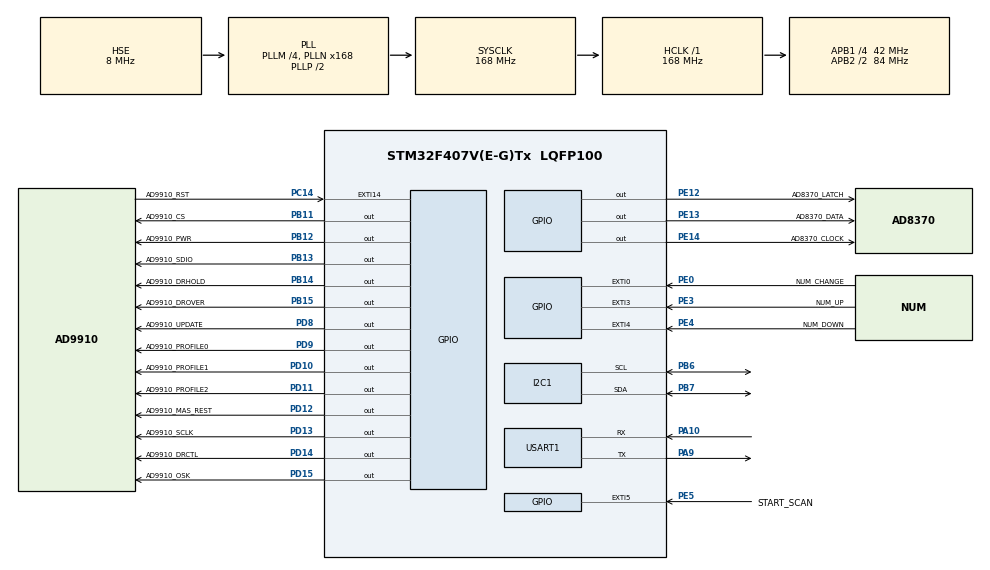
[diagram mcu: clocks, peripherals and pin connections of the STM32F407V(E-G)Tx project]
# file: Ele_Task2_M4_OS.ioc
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Mcu.Family=STM32F4
PD12.GPIO_Label=AD9910_MAS_REST
PH0-OSC_IN.Signal=RCC_OSC_IN
PE14.GPIO_Speed=GPIO_SPEED_FREQ_HIGH
RCC.CortexFreq_Value=168000000
PD15.GPIO_Speed=GPIO_SPEED_FREQ_HIGH
PB14.GPIO_Label=AD9910_DRHOLD
PD9.GPIO_Speed=GPIO_SPEED_FREQ_HIGH
NVIC.EXTI3_IRQn=true\:5\:0\:false\:false\:true\:true\:true\:true
PB13.GPIO_Label=AD9910_SDIO
PB11.Signal=GPIO_Output
PB13.Signal=GPIO_Output
PB15.Signal=GPIO_Output
FREERTOS.configUSE_TASK_NOTIFICATIONS=1
RCC.SYSCLKSource=RCC_SYSCLKSOURCE_PLLCLK
ProjectManager.StackSize=0x400
PB11.GPIO_Speed=GPIO_SPEED_FREQ_HIGH
PD13.Signal=GPIO_Output
PD14.GPIO_Speed=GPIO_SPEED_FREQ_HIGH
FREERTOS.configENABLE_FPU=1
PE5.GPIO_PuPd=GPIO_PULLUP
PD11.GPIO_Label=AD9910_PROFILE2
RCC.HCLKFreq_Value=168000000
RCC.APB2TimFreq_Value=168000000
PB6.Signal=I2C1_SCL
PB6.Mode=I2C
PD8.Signal=GPIO_Output
PE5.Signal=GPXTI5
FREERTOS.configMINIMAL_STACK_SIZE=64
RCC.AHBFreq_Value=168000000
PH0-OSC_IN.Mode=HSE-External-Oscillator
RCC.HSE_VALUE=8000000
PB12.GPIO_Label=AD9910_PWR
PE13.Signal=GPIO_Output
PA14.Mode=Serial_Wire
VP_SYS_VS_tim1.Mode=TIM1
PE4.GPIO_Label=NUM_DOWN
PB7.Signal=I2C1_SDA
FREERTOS.INCLUDE_vTaskCleanUpResources=1
PD10.GPIO_Speed=GPIO_SPEED_FREQ_HIGH
VP_FREERTOS_VS_CMSIS_V1.Mode=CMSIS_V1
PE4.Signal=GPXTI4
FREERTOS.configTOTAL_HEAP_SIZE=102400
PH1-OSC_OUT.Mode=HSE-External-Oscillator
PD13.GPIO_Label=AD9910_SCLK
Mcu.Package=LQFP100
NVIC.TimeBase=TIM1_UP_TIM10_IRQn
PD12.Signal=GPIO_Output
NVIC.TimeBaseIP=TIM1
PA10.Signal=USART1_RX
PE12.GPIO_Label=AD8370_LATCH
PE12.GPIO_Speed=GPIO_SPEED_FREQ_HIGH
PE0.GPIO_Label=NUM_CHANGE
RCC.APB2CLKDivider=RCC_HCLK_DIV2
RCC.APB1TimFreq_Value=84000000
FREERTOS.configUSE_TICK_HOOK=0
PC14-OSC32_IN.GPIO_Label=AD9910_RST
PD15.Signal=GPIO_Output
PE0.GPIO_PuPd=GPIO_PULLUP
PE3.GPIO_ModeDefaultEXTI=GPIO_MODE_IT_FALLING
RCC.PLLSourceVirtual=RCC_PLLSOURCE_HSE
NVIC.EXTI4_IRQn=true\:5\:0\:false\:false\:true\:true\:true\:true
PD12.GPIO_Speed=GPIO_SPEED_FREQ_HIGH
FREERTOS.Tasks01=None,-2,64,NoneTask,Default,NULL,Dynamic,NULL,NULL
PD15.GPIO_Label=AD9910_OSK
PD9.GPIO_Label=AD9910_PROFILE0
PA10.Mode=Asynchronous
FREERTOS.INCLUDE_vTaskDelayUntil=1
PB11.GPIO_Label=AD9910_CS
PE4.GPIO_ModeDefaultEXTI=GPIO_MODE_IT_FALLING
PE14.GPIO_Label=AD8370_CLOCK
PD9.Signal=GPIO_Output
RCC.APB1CLKDivider=RCC_HCLK_DIV4
PC14-OSC32_IN.Signal=GPXTI14
FREERTOS.configUSE_APPLICATION_TASK_TAG=1
PD8.GPIO_Label=AD9910_UPDATE
PD10.Signal=GPIO_Output
PA13.Signal=SYS_JTMS-SWDIO
FREERTOS.configUSE_IDLE_HOOK=0
PA9.Mode=Asynchronous
FREERTOS.configRECORD_STACK_HIGH_ADDRESS=0
FREERTOS.configMAX_PRIORITIES=32
ProjectManager.TargetToolchain=STM32CubeIDE
PB14.GPIO_Speed=GPIO_SPEED_FREQ_HIGH
PE5.GPIO_ModeDefaultEXTI=GPIO_MODE_IT_FALLING
I2C1.I2C_Mode=I2C_Fast
PD11.GPIO_Speed=GPIO_SPEED_FREQ_HIGH
PE0.GPIO_ModeDefaultEXTI=GPIO_MODE_IT_FALLING
PA9.Signal=USART1_TX
PB13.GPIO_Speed=GPIO_SPEED_FREQ_HIGH
PD10.GPIO_Label=AD9910_PROFILE1
RCC.LSE_VALUE=32768
PB12.GPIO_Speed=GPIO_SPEED_FREQ_HIGH
PB14.Signal=GPIO_Output
board=custom
PD13.GPIO_Speed=GPIO_SPEED_FREQ_HIGH
RCC.VCOOutputFreq_Value=336000000
RCC.APB2Freq_Value=84000000
PE14.Signal=GPIO_Output
PB15.GPIO_Label=AD9910_DROVER
PB15.GPIO_Speed=GPIO_SPEED_FREQ_HIGH
PE3.GPIO_PuPd=GPIO_PULLUP
PH1-OSC_OUT.Signal=RCC_OSC_OUT
PD14.GPIO_Label=AD9910_DRCTL
PA13.Mode=Serial_Wire
Mcu.Name=STM32F407V(E-G)Tx
PE0.Signal=GPXTI0
PE12.Signal=GPIO_Output
PE4.GPIO_PuPd=GPIO_PULLUP
PD14.Signal=GPIO_Output
RCC.48MHZClocksFreq_Value=84000000
NVIC.EXTI0_IRQn=true\:5\:0\:false\:false\:true\:true\:true\:true
RCC.SYSCLKFreq_VALUE=168000000
PE13.GPIO_Label=AD8370_DATA
FREERTOS.configUSE_COUNTING_SEMAPHORES=1
PD11.Signal=GPIO_Output
PE5.GPIO_Label=START_SCAN
USART1.VirtualMode=VM_ASYNC
PB7.Mode=I2C
NVIC.EXTI9_5_IRQn=true\:5\:0\:false\:false\:true\:true\:true\:true
PA14.Signal=SYS_JTCK-SWCLK
ProjectManager.HeapSize=0x200
FREERTOS.configUSE_RECURSIVE_MUTEXES=1
NVIC.TIM1_UP_TIM10_IRQn=true\:0\:0\:false\:false\:true\:false\:false\:true
RCC.HSI_VALUE=16000000
PD8.GPIO_Speed=GPIO_SPEED_FREQ_HIGH
NVIC.PriorityGroup=NVIC_PRIORITYGROUP_4
RCC.PLLM=4
RCC.PLLN=168
PE13.GPIO_Speed=GPIO_SPEED_FREQ_HIGH
PE3.Signal=GPXTI3
PE3.GPIO_Label=NUM_UP
RCC.APB1Freq_Value=42000000
PB12.Signal=GPIO_Output

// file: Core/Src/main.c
/* USER CODE BEGIN Header */
/**
  ******************************************************************************
  * @file           : main.c
  * @brief          : Main program body
  ******************************************************************************
  * @attention
  *
  * <h2><center>&copy; Copyright (c) 2021 STMicroelectronics.
  * All rights reserved.</center></h2>
  *
  * This software component is licensed by ST under Ultimate Liberty license
  * SLA0044, the "License"; You may not use this file except in compliance with
  * the License. You may obtain a copy of the License at:
  *                             www.st.com/SLA0044
  *
  ******************************************************************************
  */
/* USER CODE END Header */
#include "main.h"
#include "cmsis_os.h"
#include "i2c.h"
#include "usart.h"
#include "gpio.h"

/* USER CODE BEGIN Includes */
#include "../Driver/HAL_Support/HAL_Fix.h"
/* USER CODE END Includes */

void SystemClock_Config(void);
void MX_FREERTOS_Init(void);

int main(void)
{

    /* MCU Configuration--------------------------------------------------------*/

    /* Reset of all peripherals, Initializes the Flash interface and the Systick. */
    HAL_Init();

    /* USER CODE BEGIN Init */
    HAL_Fix();
    /* USER CODE END Init */

    /* Configure the system clock */
    SystemClock_Config();

    /* Initialize all configured peripherals */
    MX_GPIO_Init();
    MX_I2C1_Init();
    MX_USART1_UART_Init();

    /* Call init function for freertos objects (in freertos.c) */
    MX_FREERTOS_Init();
    /* Start scheduler */
    osKernelStart();

    /* We should never get here as control is now taken by the scheduler */
    /* Infinite loop */
    while (1)
    {

    }
}

void SystemClock_Config(void)
{
    RCC_OscInitTypeDef RCC_OscInitStruct = {0};
    RCC_ClkInitTypeDef RCC_ClkInitStruct = {0};

    /** Configure the main internal regulator output voltage
    */
    __HAL_RCC_PWR_CLK_ENABLE();
    __HAL_PWR_VOLTAGESCALING_CONFIG(PWR_REGULATOR_VOLTAGE_SCALE1);
    /** Initializes the RCC Oscillators according to the specified parameters
    * in the RCC_OscInitTypeDef structure.
    */
    RCC_OscInitStruct.OscillatorType = RCC_OSCILLATORTYPE_HSE;
    RCC_OscInitStruct.HSEState = RCC_HSE_ON;
    RCC_OscInitStruct.PLL.PLLState = RCC_PLL_ON;
    RCC_OscInitStruct.PLL.PLLSource = RCC_PLLSOURCE_HSE;
    RCC_OscInitStruct.PLL.PLLM = 4;
    RCC_OscInitStruct.PLL.PLLN = 168;
    RCC_OscInitStruct.PLL.PLLP = RCC_PLLP_DIV2;
    RCC_OscInitStruct.PLL.PLLQ = 4;
    if (HAL_RCC_OscConfig(&RCC_OscInitStruct) != HAL_OK)
    {
        Error_Handler();
    }
    /** Initializes the CPU, AHB and APB buses clocks
    */
    RCC_ClkInitStruct.ClockType = RCC_CLOCKTYPE_HCLK | RCC_CLOCKTYPE_SYSCLK
                                  | RCC_CLOCKTYPE_PCLK1 | RCC_CLOCKTYPE_PCLK2;
    RCC_ClkInitStruct.SYSCLKSource = RCC_SYSCLKSOURCE_PLLCLK;
    RCC_ClkInitStruct.AHBCLKDivider = RCC_SYSCLK_DIV1;
    RCC_ClkInitStruct.APB1CLKDivider = RCC_HCLK_DIV4;
    RCC_ClkInitStruct.APB2CLKDivider = RCC_HCLK_DIV2;

    if (HAL_RCC_ClockConfig(&RCC_ClkInitStruct, FLASH_LATENCY_5) != HAL_OK)
    {
        Error_Handler();
    }
}

void HAL_TIM_PeriodElapsedCallback(TIM_HandleTypeDef *htim)
{
    if (htim->Instance == TIM1)
    {
        HAL_IncTick();
    }
}

void Error_Handler(void)
{
    __disable_irq();
    while (1)
    {
    }
}

/************************ (C) COPYRIGHT STMicroelectronics *****END OF FILE****/

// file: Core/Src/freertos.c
/* USER CODE BEGIN Header */
/**
  ******************************************************************************
  * File Name          : freertos.c
  * Description        : Code for freertos applications
  ******************************************************************************
  * @attention
  *
  * <h2><center>&copy; Copyright (c) 2021 STMicroelectronics.
  * All rights reserved.</center></h2>
  *
  * This software component is licensed by ST under Ultimate Liberty license
  * SLA0044, the "License"; You may not use this file except in compliance with
  * the License. You may obtain a copy of the License at:
  *                             www.st.com/SLA0044
  *
  ******************************************************************************
  */
/* USER CODE END Header */

#include "FreeRTOS.h"
#include "task.h"
#include "main.h"
#include "cmsis_os.h"

/* USER CODE BEGIN Includes */
#include "usart.h"
#include "../Driver/HAL_Support/Retarget/retarget.h"
#include "../User/OSThreadHandler/OSThreadHandler.h"
/* USER CODE END Includes */

osThreadId NoneHandle;

void NoneTask(void const * argument);

void MX_FREERTOS_Init(void); /* (MISRA C 2004 rule 8.1) */

/* GetIdleTaskMemory prototype (linked to static allocation support) */
void vApplicationGetIdleTaskMemory( StaticTask_t **ppxIdleTaskTCBBuffer, StackType_t **ppxIdleTaskStackBuffer, uint32_t *pulIdleTaskStackSize );

/* USER CODE BEGIN GET_IDLE_TASK_MEMORY */
static StaticTask_t xIdleTaskTCBBuffer;
static StackType_t xIdleStack[configMINIMAL_STACK_SIZE];

void vApplicationGetIdleTaskMemory(StaticTask_t **ppxIdleTaskTCBBuffer, StackType_t **ppxIdleTaskStackBuffer, uint32_t *pulIdleTaskStackSize)
{
    *ppxIdleTaskTCBBuffer = &xIdleTaskTCBBuffer;
    *ppxIdleTaskStackBuffer = &xIdleStack[0];
    *pulIdleTaskStackSize = configMINIMAL_STACK_SIZE;
    /* place for user code */
}
/* USER CODE END GET_IDLE_TASK_MEMORY */

void MX_FREERTOS_Init(void) {

  /* Create the thread(s) */
  /* definition and creation of None */
  osThreadDef(None, NoneTask, osPriorityLow, 0, 64);
  NoneHandle = osThreadCreate(osThread(None), NULL);

  /* USER CODE BEGIN RTOS_THREADS */
    /* add threads, ... */
    InitializeTask();
  /* USER CODE END RTOS_THREADS */

}

void NoneTask(void const * argument)
{
  /* USER CODE BEGIN NoneTask */
    /* Infinite loop */
    vTaskDelete(NULL);
  /* USER CODE END NoneTask */
}

/************************ (C) COPYRIGHT STMicroelectronics *****END OF FILE****/
